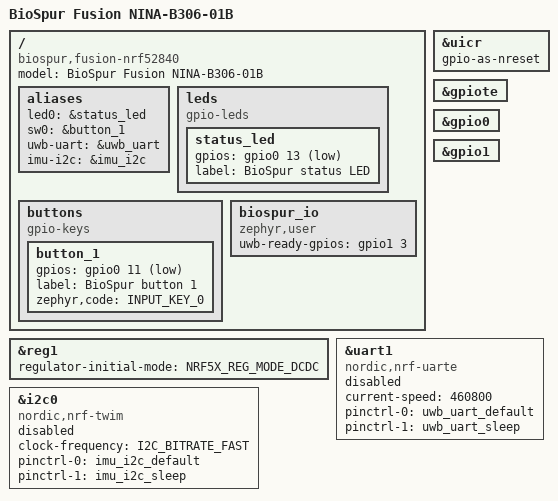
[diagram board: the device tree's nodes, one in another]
/*
 * BioSpur Fusion PCB: u-blox NINA-B306-01B (nRF52840)
 *
 * SPDX-License-Identifier: Apache-2.0
 */

/dts-v1/;
#include <nordic/nrf52840_qiaa.dtsi>
#include <nordic/nrf52840_partition.dtsi>
#include "biospur_fusion_nrf52840_nrf52840-pinctrl.dtsi"
#include <zephyr/dt-bindings/input/input-event-codes.h>

/ {
	model = "BioSpur Fusion NINA-B306-01B";
	compatible = "biospur,fusion-nrf52840";

	/*
	 * These aliases describe physical PCB wiring. The UART and I2C
	 * controllers remain disabled in the first DFU image and are enabled
	 * only by the later ingest firmware.
	 */
	aliases {
		led0 = &status_led;
		sw0 = &button_1;
		uwb-uart = &uwb_uart;
		imu-i2c = &imu_i2c;
	};

	leds {
		compatible = "gpio-leds";

		status_led: status_led {
			/* NINA GPIO_1; LED and 220 ohm resistor return to +3V3. */
			gpios = <&gpio0 13 GPIO_ACTIVE_LOW>;
			label = "BioSpur status LED";
		};
	};

	buttons {
		compatible = "gpio-keys";

		button_1: button_1 {
			/* NINA GPIO_32. */
			gpios = <&gpio0 11 (GPIO_PULL_UP | GPIO_ACTIVE_LOW)>;
			label = "BioSpur button 1";
			zephyr,code = <INPUT_KEY_0>;
		};
	};

	biospur_io: biospur_io {
		compatible = "zephyr,user";

		/* NINA GPIO_37: sweep strobe input from DWM1001C P0.26. */
		uwb-ready-gpios = <&gpio1 3 GPIO_ACTIVE_HIGH>;
	};
};

&reg1 {
	regulator-initial-mode = <NRF5X_REG_MODE_DCDC>;
};

&uicr {
	gpio-as-nreset;
};

&gpiote {
	status = "okay";
};

&gpio0 {
	status = "okay";
};

&gpio1 {
	status = "okay";
};

uwb_uart: &uart1 {
	compatible = "nordic,nrf-uarte";
	current-speed = <460800>;
	pinctrl-0 = <&uwb_uart_default>;
	pinctrl-1 = <&uwb_uart_sleep>;
	pinctrl-names = "default", "sleep";
	status = "disabled";
};

imu_i2c: &i2c0 {
	compatible = "nordic,nrf-twim";
	clock-frequency = <I2C_BITRATE_FAST>;
	pinctrl-0 = <&imu_i2c_default>;
	pinctrl-1 = <&imu_i2c_sleep>;
	pinctrl-names = "default", "sleep";
	status = "disabled";
};
